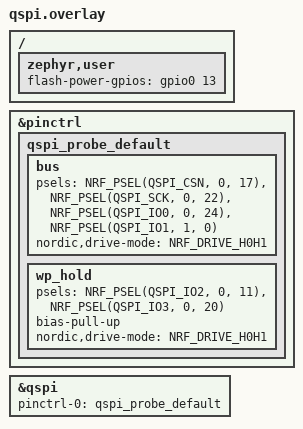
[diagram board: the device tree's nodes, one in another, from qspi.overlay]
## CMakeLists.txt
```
cmake_minimum_required(VERSION 3.20.0)
option(JAVELIN_PROBE "Run the native Javelin dictionary reader from external flash" OFF)
if(JAVELIN_PROBE)
  list(APPEND EXTRA_CONF_FILE "${CMAKE_CURRENT_SOURCE_DIR}/javelin.conf")
endif()
find_package(Zephyr REQUIRED HINTS $ENV{ZEPHYR_BASE})
project(zen_r4_qspi_probe)
target_sources(app PRIVATE src/main.c)

option(QUAD_PROBE "Build the separate quad-read diagnostic image" OFF)
option(SCRATCH_PROBE "Build the scratch-sector program and erase diagnostic image" OFF)
option(TRACE_PROBE "Repeat quad reads for waveform capture and timing comparison" OFF)
option(XIP_PROBE "Compare mapped quad reads with EasyDMA" OFF)
if(TRACE_PROBE AND NOT SCRATCH_PROBE)
  message(FATAL_ERROR "TRACE_PROBE requires SCRATCH_PROBE")
endif()
if(XIP_PROBE AND (NOT SCRATCH_PROBE OR TRACE_PROBE))
  message(FATAL_ERROR "XIP_PROBE requires SCRATCH_PROBE and a separate build from TRACE_PROBE")
endif()
if(JAVELIN_PROBE AND (NOT SCRATCH_PROBE OR XIP_PROBE OR TRACE_PROBE))
  message(FATAL_ERROR "JAVELIN_PROBE requires SCRATCH_PROBE and its own build directory")
endif()
if(QUAD_PROBE OR SCRATCH_PROBE)
  target_sources(app PRIVATE src/quad.c)
  target_compile_definitions(app PRIVATE QUAD_PROBE=1)
endif()
if(SCRATCH_PROBE)
  target_sources(app PRIVATE src/scratch.c)
  target_compile_definitions(app PRIVATE SCRATCH_PROBE=1)
endif()
if(TRACE_PROBE)
  target_sources(app PRIVATE src/trace.c)
  target_compile_definitions(app PRIVATE TRACE_PROBE=1)
endif()
if(XIP_PROBE OR JAVELIN_PROBE)
  target_sources(app PRIVATE src/mapped.c)
endif()
if(XIP_PROBE)
  target_compile_definitions(app PRIVATE XIP_PROBE=1)
endif()
if(JAVELIN_PROBE)
  include(javelin.cmake)
endif()
```

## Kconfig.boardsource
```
# The vendor board defconfig also configures the ZMK application. Declare
# those settings here so the same board can build this standalone probe.
source "Kconfig.zephyr"

config ZMK_KEYBOARD_NAME
	string

config ZMK_SPLIT_ROLE_CENTRAL
	bool

config ZMK_SPLIT
	bool

config ZMK_USB
	bool "Vendor ZMK USB default"

config ZMK_STUDIO
	bool "Vendor ZMK Studio default"

config ZMK_STUDIO_LOCKING
	bool "Vendor ZMK Studio locking default"

config ZMK_BLE
	bool "Vendor ZMK BLE default"

config ZMK_SLEEP
	bool "Vendor ZMK sleep default"

config ZMK_DISPLAY
	bool

config ZMK_DISPLAY_BLANK_ON_IDLE
	bool
```

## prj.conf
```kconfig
CONFIG_GPIO=y
CONFIG_PINCTRL=y
CONFIG_NRFX_QSPI=y

CONFIG_BUILD_OUTPUT_UF2=y
CONFIG_BUILD_OUTPUT_UF2_FAMILY_ID="0xada52840"
CONFIG_USE_DT_CODE_PARTITION=y

CONFIG_USB_DEVICE_STACK=y
CONFIG_USB_DEVICE_INITIALIZE_AT_BOOT=n
CONFIG_USB_DEVICE_PRODUCT="Zen R4 QSPI Probe"
CONFIG_SERIAL=y
CONFIG_CONSOLE=y
CONFIG_UART_CONSOLE=y
CONFIG_UART_LINE_CTRL=y

CONFIG_LOG=y
CONFIG_LOG_MODE_IMMEDIATE=y
CONFIG_LOG_PRINTK=n
CONFIG_USE_SEGGER_RTT=y
CONFIG_LOG_BACKEND_RTT=y
CONFIG_LOG_BACKEND_UART=n
```

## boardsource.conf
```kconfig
# The standalone probe uses nrfx QSPI and never uses Zephyr SPI or NVS settings.
CONFIG_SPI_NRFX=n
CONFIG_NVS=n
CONFIG_FLASH_MAP=n
CONFIG_FLASH_PAGE_LAYOUT=n
CONFIG_FLASH=n
CONFIG_ZMK_USB=n
CONFIG_ZMK_STUDIO=n
CONFIG_ZMK_BLE=n
CONFIG_ZMK_SLEEP=n
CONFIG_USB_DEVICE_PRODUCT="Boardsource QSPI Probe"
```

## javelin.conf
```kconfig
CONFIG_CPP=y
CONFIG_STD_CPP20=y
CONFIG_MAIN_STACK_SIZE=3072
```

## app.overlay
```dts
#include "qspi.overlay"

/ {
	chosen {
		zephyr,console = &probe_cdc;
	};
};

&zephyr_udc0 {
	probe_cdc: probe_cdc {
		compatible = "zephyr,cdc-acm-uart";
	};
};
```

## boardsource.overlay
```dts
#include "../../config/boardsource-wireless-corne/qspi.dtsi"

/ {
	chosen {
		zephyr,console = &probe_cdc;
	};
};

&zephyr_udc0 {
	probe_cdc: probe_cdc {
		compatible = "zephyr,cdc-acm-uart";
	};
};
```

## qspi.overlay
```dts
#include <zephyr/dt-bindings/gpio/gpio.h>
#include <zephyr/dt-bindings/pinctrl/nrf-pinctrl.h>

/ {
	zephyr,user {
		flash-power-gpios = <&gpio0 13 GPIO_ACTIVE_HIGH>;
	};
};

&pinctrl {
	qspi_probe_default: qspi_probe_default {
		bus {
			psels = <NRF_PSEL(QSPI_CSN, 0, 17)>,
				<NRF_PSEL(QSPI_SCK, 0, 22)>,
				<NRF_PSEL(QSPI_IO0, 0, 24)>,
				<NRF_PSEL(QSPI_IO1, 1, 0)>;
			nordic,drive-mode = <NRF_DRIVE_H0H1>;
		};
		wp_hold {
			psels = <NRF_PSEL(QSPI_IO2, 0, 11)>,
				<NRF_PSEL(QSPI_IO3, 0, 20)>;
			bias-pull-up;
			nordic,drive-mode = <NRF_DRIVE_H0H1>;
		};
	};
};

&qspi {
	status = "okay";
	pinctrl-0 = <&qspi_probe_default>;
	pinctrl-names = "default";
};
```

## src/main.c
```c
#include <nrfx_qspi.h>

#ifdef QUAD_PROBE
#include "quad.h"
#endif
#ifdef SCRATCH_PROBE
#include "scratch.h"
#endif

#include <zephyr/device.h>
#include <zephyr/devicetree.h>
#include <zephyr/drivers/gpio.h>
#include <zephyr/drivers/pinctrl.h>
#include <zephyr/drivers/uart.h>
#include <zephyr/kernel.h>
#include <zephyr/logging/log.h>
#include <zephyr/sys/printk.h>
#include <zephyr/usb/usb_device.h>

LOG_MODULE_REGISTER(qspi_probe);

#define QSPI_NODE DT_NODELABEL(qspi)

PINCTRL_DT_DEFINE(QSPI_NODE);

static const struct gpio_dt_spec flash_power =
	GPIO_DT_SPEC_GET(DT_PATH(zephyr_user), flash_power_gpios);
static const struct gpio_dt_spec status_led =
	GPIO_DT_SPEC_GET(DT_NODELABEL(blue_led), gpios);
static const struct device *const console = DEVICE_DT_GET(DT_CHOSEN(zephyr_console));

static const nrf_qspi_cinstr_conf_t read_id = {
	.opcode = 0x9f,
	.length = NRF_QSPI_CINSTR_LEN_4B,
	.io2_level = true,
	.io3_level = true,
	.wipwait = false,
	.wren = false,
};

struct probe_result {
	const char *failure;
	int gpio_or_pinctrl_error;
	nrfx_err_t nrfx_error;
	bool id_read;
	uint8_t id[3];
	uint8_t data[16] __aligned(4);
#ifdef QUAD_PROBE
	struct quad_result quad;
#endif
#ifdef SCRATCH_PROBE
	struct scratch_result scratch;
#endif
};

static void run_probe(struct probe_result *result)
{
	nrfx_qspi_config_t config = NRFX_QSPI_DEFAULT_CONFIG(
		NRF_QSPI_PIN_NOT_CONNECTED, NRF_QSPI_PIN_NOT_CONNECTED,
		NRF_QSPI_PIN_NOT_CONNECTED, NRF_QSPI_PIN_NOT_CONNECTED,
		NRF_QSPI_PIN_NOT_CONNECTED, NRF_QSPI_PIN_NOT_CONNECTED);

	/* Zephyr pinctrl supplies both the pin assignments and GPIO configuration. */
	config.skip_gpio_cfg = true;
	config.skip_psel_cfg = true;
	config.phy_if.sck_freq = NRF_QSPI_FREQ_DIV16;

	printk("Enabling switched flash VCC\n");
	if (!gpio_is_ready_dt(&flash_power)) {
		result->failure = "VCC GPIO device unavailable";
		return;
	}
	result->gpio_or_pinctrl_error = gpio_pin_configure_dt(&flash_power, GPIO_OUTPUT_ACTIVE);
	if (result->gpio_or_pinctrl_error) {
		result->failure = "VCC GPIO configuration";
		return;
	}
	k_msleep(50);

	printk("Applying QSPI pinctrl\n");
	result->gpio_or_pinctrl_error =
		pinctrl_apply_state(PINCTRL_DT_DEV_CONFIG_GET(QSPI_NODE), PINCTRL_STATE_DEFAULT);
	if (result->gpio_or_pinctrl_error) {
		result->failure = "QSPI pinctrl";
		return;
	}

	printk("Initializing Nordic QSPI (2 MHz, FASTREAD, 24-bit address)\n");
	result->nrfx_error = nrfx_qspi_init(&config, NULL, NULL);
	if (result->nrfx_error != NRFX_SUCCESS) {
		result->failure = "nrfx_qspi_init";
		return;
	}

	printk("Activating QSPI\n");
	result->nrfx_error = nrfx_qspi_activate(true);
	if (result->nrfx_error != NRFX_SUCCESS) {
		result->failure = "nrfx_qspi_activate";
		return;
	}

	printk("Reading JEDEC ID (0x9F)\n");
	result->nrfx_error = nrfx_qspi_cinstr_xfer(&read_id, NULL, result->id);
	if (result->nrfx_error != NRFX_SUCCESS) {
		result->failure = "JEDEC ID transfer";
		return;
	}
	result->id_read = true;

	if (result->id[0] != 0xef || result->id[1] != 0x40 || result->id[2] != 0x18) {
		result->failure = "unexpected JEDEC ID";
		return;
	}

	printk("Reading 16 bytes at 0x000000 with FASTREAD (0x0B)\n");
	result->nrfx_error = nrfx_qspi_read(result->data, sizeof(result->data), 0);
	if (result->nrfx_error != NRFX_SUCCESS) {
		result->failure = "FASTREAD transfer";
		return;
	}
#ifdef SCRATCH_PROBE
	run_scratch_probe(&config, &result->scratch, &result->quad);
#elif defined(QUAD_PROBE)
	run_quad_probe(&config, &result->quad, 0, 64 * 1024);
#endif
}

static void print_result(const struct probe_result *result)
{
	if (result->id_read) {
		printk("JEDEC ID: %02X %02X %02X (expected EF 40 18)\n",
		       result->id[0], result->id[1], result->id[2]);
	}
	if (result->failure) {
		printk("FAIL: %s; Zephyr rc=%d, nrfx rc=0x%08x\n",
		       result->failure, result->gpio_or_pinctrl_error, (unsigned int)result->nrfx_error);
		return;
	}

	printk("FASTREAD 0x000000:");
	for (size_t i = 0; i < sizeof(result->data); i++) {
		printk(" %02X", result->data[i]);
	}
#ifdef SCRATCH_PROBE
	printk("\nScratch %s (nrfx rc=0x%08x)\n",
	       result->scratch.outcome, (unsigned int)result->scratch.error);
	if (result->scratch.cleanup) {
		printk("Scratch cleanup %s (nrfx rc=0x%08x)\n",
		       result->scratch.cleanup, (unsigned int)result->scratch.cleanup_error);
	}
#endif
#ifdef QUAD_PROBE
	if (result->quad.outcome) {
		printk("\nQuad %s (compared %u bytes, lane mask 0x%x, nrfx rc=0x%08x)\n",
		       result->quad.outcome, result->quad.compared_bytes, result->quad.lane_coverage,
		       (unsigned int)result->quad.error);
#ifdef XIP_PROBE
		if (result->quad.mapped.outcome) {
			printk("XIP %s (matched %u words, nrfx rc=0x%08x)\n",
			       result->quad.mapped.outcome, result->quad.mapped.matched_words,
			       (unsigned int)result->quad.mapped.dma_error);
		}
#endif
#ifdef JAVELIN_PROBE
		if (result->quad.javelin_outcome) {
			printk("Javelin %s\n", result->quad.javelin_outcome);
			if (result->quad.phrase[0]) {
				printk("Javelin phrase: %s\n", result->quad.phrase);
			}
		}
#endif
		if (result->quad.restore_error != NRFX_SUCCESS) {
			printk("Quad SR2 restore failed: nrfx rc=0x%08x; power-cycle the flash\n",
			       (unsigned int)result->quad.restore_error);
		}
	}
#else
	printk("\nPASS: JEDEC ID and 16-byte single-data-line read completed\n");
#endif
}

int main(void)
{
	struct probe_result result = {.nrfx_error = NRFX_SUCCESS};
	uint32_t dtr = 0;
	bool led_ready = gpio_is_ready_dt(&status_led) &&
			 gpio_pin_configure_dt(&status_led, GPIO_OUTPUT_ACTIVE) == 0;
	int rc = device_is_ready(console) ? usb_enable(NULL) : -ENODEV;

	if (rc) {
		LOG_ERR("USB CDC startup failed: %d", rc);
		for (;;) {
			if (led_ready) {
				gpio_pin_toggle_dt(&status_led);
			}
			k_msleep(120);
		}
	}

	while (!dtr) {
		rc = uart_line_ctrl_get(console, UART_LINE_CTRL_DTR, &dtr);
		if (rc) {
			LOG_ERR("CDC DTR query failed: %d", rc);
		}
		k_msleep(100);
	}
	if (led_ready) {
		gpio_pin_set_dt(&status_led, 0);
	}

#ifdef TRACE_PROBE
	printk("\nZen R4 QSPI trace ready. Arm the analyzer, then send t.\n");
	for (;;) {
		unsigned char key;

		if (uart_poll_in(console, &key) == 0 && key == 't') {
			break;
		}
		k_msleep(20);
	}
#elif defined(XIP_PROBE)
	printk("\nZen R4 QSPI probe - mapped quad data reads\n");
#elif defined(JAVELIN_PROBE)
	printk("\nZen R4 QSPI probe - native Javelin mapped dictionary\n");
#elif defined(SCRATCH_PROBE)
	printk("\nZen R4 QSPI probe - scratch-sector program, read and erase\n");
#elif defined(QUAD_PROBE)
	printk("\n%s - quad output with volatile QE if needed\n", CONFIG_USB_DEVICE_PRODUCT);
#else
	printk("\n%s - read only\n", CONFIG_USB_DEVICE_PRODUCT);
#endif
	run_probe(&result);
	for (;;) {
		print_result(&result);
		k_sleep(K_SECONDS(3));
	}
}
```

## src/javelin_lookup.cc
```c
#include "javelin_lookup.h"

#include "console.h"
#include "dictionary/compact_map_dictionary.h"
#include "dictionary/dictionary_definition.h"
#include "flash.h"
#include "xip_load.h"

#include <nrf.h>
#include <nrf52_erratas.h>
#include <string.h>
#include <zephyr/kernel.h>
#include <zephyr/sys/printk.h>

// These hooks belong to dictionary editing and console commands. This image
// exercises read-only lookups, so editing must never reach the flash driver.
void Flash::Write(const void *, const void *, size_t, FlashWriteMode)
{
	k_panic();
}

void Console::PrintfInternal(const char *, ...)
{
}

ConsoleWriter::ClassData ConsoleWriter::classData{};

const char *javelin_lookup_phrase(uintptr_t address, char *phrase)
{
	printk("Using synchronized XIP loads (erratum 118: %u, erratum 216: %u)\n",
	       nrf52_errata_118(), nrf52_errata_216());
	const auto *collection = reinterpret_cast<const uint8_t *>(address);
	if (xip_load_word(collection) != STENO_MAP_DICTIONARY_COLLECTION_MAGIC ||
	    (xip_load_word(collection + offsetof(StenoDictionaryCollection, dictionaryCount)) &
	     0xffff) != 1) {
		return "FAIL: mapped JSC4 header";
	}
	const auto definition_address =
		xip_load_word(collection + offsetof(StenoDictionaryCollection, dictionaries));
	const auto fixture_end = address + (javelin_fixture_end - javelin_fixture_start);
	if (definition_address < address ||
	    definition_address > fixture_end - sizeof(StenoCompactMapDictionaryDefinition)) {
		return "FAIL: mapped definition address";
	}
	StenoCompactMapDictionaryDefinition definition;
	copy_xip_bytes(&definition, reinterpret_cast<const void *>(definition_address),
		       sizeof(definition));
	if (definition.type != StenoDictionaryType::COMPACT_MAP ||
	    definition.maximumOutlineLength != 1) {
		return "FAIL: mapped compact dictionary definition";
	}
	StenoCompactMapDictionaryStrokesDefinition stroke_table;
	copy_xip_bytes(&stroke_table, definition.strokes, sizeof(stroke_table));
	definition.strokes = &stroke_table;
	auto *dictionary = new (definition) StenoCompactMapDictionary(definition);
	if (!dictionary) {
		return "FAIL: dictionary allocation";
	}

	const struct {
		uint32_t stroke;
		const char *outline;
		const char *expected;
	} strokes[] = {
		{0x14, "TP", "if"}, {0x80000, "-T", "the"}, {0x80108, "KAT", "cat"},
		{0x2, "S", "is"}, {0x80000, "-T", "the"}, {0x80108, "KAT", "cat"},
	};
	const char *outcome = "PASS: native Javelin lookups used mapped external flash";
	size_t size = 0;
	phrase[0] = '\0';
	for (const auto &step : strokes) {
		const StenoStroke stroke(step.stroke);
		auto result = dictionary->Lookup(&stroke, 1);
		if (!result.IsValid()) {
			outcome = "FAIL: native lookup returned no entry";
			break;
		}
		const char *word = result.GetText();
		const auto word_address = reinterpret_cast<uintptr_t>(word);
		const auto expected_size = strlen(step.expected);
		char word_copy[4];
		if (word_address < address || word_address >= fixture_end ||
		    fixture_end - word_address <= expected_size || expected_size >= sizeof(word_copy)) {
			outcome = "FAIL: native lookup did not return a mapped text address";
			result.Destroy();
			break;
		}
		copy_xip_bytes(word_copy, word, expected_size + 1);
		if (memcmp(word_copy, step.expected, expected_size + 1) != 0) {
			outcome = "FAIL: mapped lookup text differed from expected";
			result.Destroy();
			break;
		}
		printk("Native stroke %s -> %s at 0x%08x\n", step.outline, word_copy,
		       static_cast<unsigned int>(word_address));
		if (size) {
			phrase[size++] = ' ';
		}
		memcpy(phrase + size, word_copy, expected_size + 1);
		size += expected_size;
		result.Destroy();
	}
	delete dictionary;
	return outcome;
}
```

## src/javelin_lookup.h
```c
#ifndef ZEN_R4_JAVELIN_LOOKUP_H
#define ZEN_R4_JAVELIN_LOOKUP_H

#include <stdint.h>

#ifdef __cplusplus
extern "C" {
#endif

extern const uint8_t javelin_fixture_start[];
extern const uint8_t javelin_fixture_end[];

const char *javelin_lookup_phrase(uintptr_t address, char *phrase);
#define JAVELIN_PHRASE_SIZE 32

#ifdef __cplusplus
}
#endif

#endif
```

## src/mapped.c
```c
#include "mapped.h"
#include "scratch.h"

#include <zephyr/devicetree.h>
#include <zephyr/kernel.h>
#include <zephyr/sys/printk.h>

#define XIP_BASE DT_REG_ADDR_BY_NAME(DT_NODELABEL(qspi), qspi_mm)
#define PAGE_WORDS (QUAD_SAMPLE_SIZE / sizeof(uint32_t))

static uint32_t dma_page[2][PAGE_WORDS];

bool reactivate_after_xip(void)
{
	/* nRF52840 anomaly 215. Use only task/event registers until READY. */
	nrf_qspi_event_clear(NRF_QSPI, NRF_QSPI_EVENT_READY);
	nrf_qspi_task_trigger(NRF_QSPI, NRF_QSPI_TASK_ACTIVATE);
	for (unsigned int i = 0; i < 1000; i++) {
		if (nrf_qspi_event_check(NRF_QSPI, NRF_QSPI_EVENT_READY)) {
			nrf_qspi_event_clear(NRF_QSPI, NRF_QSPI_EVENT_READY);
			return true;
		}
		k_busy_wait(10);
	}
	return false;
}

void run_mapped_probe(struct mapped_result *result, uint32_t first_address)
{
	const uint32_t addresses[] = {first_address, result->second_address};
	const uint8_t patterns[] = {SCRATCH_FIRST_PATTERN, SCRATCH_SECOND_PATTERN};
	uintptr_t mismatch_address = 0;
	uint32_t mismatch_expected = 0;
	uint32_t mismatch_actual = 0;

	for (size_t page = 0; page < ARRAY_SIZE(addresses); page++) {
		result->dma_error = nrfx_qspi_read(dma_page[page], sizeof(dma_page[page]),
						 addresses[page]);
		if (result->dma_error != NRFX_SUCCESS) {
			result->outcome = "FAIL: quad EasyDMA reference read";
			return;
		}
		const uint8_t *reference = (const uint8_t *)dma_page[page];

		for (size_t byte = 0; byte < sizeof(dma_page[page]); byte++) {
			if (reference[byte] != ((uint8_t)byte ^ patterns[page])) {
				printk("Quad EasyDMA pattern mismatch at 0x%06x\n",
				       addresses[page] + (unsigned int)byte);
				result->outcome = "FAIL: quad EasyDMA reference differs from programmed pattern";
				return;
			}
		}
	}

	printk("Reading mapped quad pages at 0x%08x and 0x%08x\n",
	       (unsigned int)(XIP_BASE + addresses[0]), (unsigned int)(XIP_BASE + addresses[1]));
	for (size_t page = 0; page < ARRAY_SIZE(addresses); page++) {
		const volatile uint32_t *mapped =
			(const volatile uint32_t *)(XIP_BASE + addresses[page]);

		for (size_t word = 0; word < PAGE_WORDS; word++) {
			uint32_t actual = mapped[word];
			uint32_t expected = dma_page[page][word];

			if (actual == expected) {
				result->matched_words++;
			} else if (mismatch_address == 0) {
				mismatch_address = (uintptr_t)&mapped[word];
				mismatch_expected = expected;
				mismatch_actual = actual;
			}
		}
	}

	if (!reactivate_after_xip()) {
		result->reactivation_failed = true;
		result->outcome = "FAIL: QSPI did not become ready after mapped reads";
		return;
	}
	if (mismatch_address) {
		printk("Mapped mismatch at 0x%08x: expected %08x, got %08x\n",
		       (unsigned int)mismatch_address, mismatch_expected, mismatch_actual);
		result->outcome = "FAIL: mapped reads differ from quad EasyDMA";
		return;
	}
	result->outcome = "PASS: both mapped pages match quad EasyDMA";
}
```

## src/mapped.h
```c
#ifndef ZEN_R4_MAPPED_H
#define ZEN_R4_MAPPED_H

#include <nrfx_qspi.h>

struct mapped_result {
	const char *outcome;
	uint32_t second_address;
	unsigned int matched_words;
	nrfx_err_t dma_error;
	bool reactivation_failed;
};

void run_mapped_probe(struct mapped_result *result, uint32_t first_address);

#endif
```

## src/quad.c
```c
#include "quad.h"
#ifdef TRACE_PROBE
#include "trace.h"
#endif
#ifdef JAVELIN_PROBE
#include "mapped.h"
#include <zephyr/devicetree.h>
#endif

#include <string.h>
#include <zephyr/kernel.h>
#include <zephyr/sys/printk.h>

#define QUAD_ENABLE BIT(1)
#define STATUS_BUSY_OR_WRITE_ENABLED (BIT(0) | BIT(1))
static uint8_t single_data[QUAD_SAMPLE_SIZE] __aligned(4);
static uint8_t quad_data[QUAD_SAMPLE_SIZE] __aligned(4);

bool reactivate_after_xip(void)
{
	/* nRF52840 anomaly 215. Use only task/event registers until READY. */
	nrf_qspi_event_clear(NRF_QSPI, NRF_QSPI_EVENT_READY);
	nrf_qspi_task_trigger(NRF_QSPI, NRF_QSPI_TASK_ACTIVATE);
	for (unsigned int i = 0; i < 1000; i++) {
		if (nrf_qspi_event_check(NRF_QSPI, NRF_QSPI_EVENT_READY)) {
			nrf_qspi_event_clear(NRF_QSPI, NRF_QSPI_EVENT_READY);
			return true;
		}
		k_busy_wait(10);
	}
	return false;
}

static nrfx_err_t status_command(uint8_t opcode, const uint8_t *tx, uint8_t *rx)
{
	const nrf_qspi_cinstr_conf_t command = {
		.opcode = opcode,
		.length = tx || rx ? NRF_QSPI_CINSTR_LEN_2B : NRF_QSPI_CINSTR_LEN_1B,
		.io2_level = true,
		.io3_level = true,
		.wipwait = false,
		.wren = false,
	};

	return nrfx_qspi_cinstr_xfer(&command, tx, rx);
}

static nrfx_err_t set_volatile_sr2(uint8_t value)
{
	uint8_t status;
	nrfx_err_t rc = status_command(0x05, NULL, &status);

	if (rc != NRFX_SUCCESS) {
		return rc;
	}
	/* A preexisting WEL could turn the SR2 write into a nonvolatile write. */
	if (status & STATUS_BUSY_OR_WRITE_ENABLED) {
		return NRFX_ERROR_BUSY;
	}

	rc = status_command(0x50, NULL, NULL);
	if (rc != NRFX_SUCCESS) {
		return rc;
	}
	rc = status_command(0x31, &value, NULL);
	if (rc != NRFX_SUCCESS) {
		return rc;
	}

	k_msleep(2);
	rc = status_command(0x35, NULL, &status);
	if (rc != NRFX_SUCCESS) {
		return rc;
	}
	return status == value ? NRFX_SUCCESS : NRFX_ERROR_INTERNAL;
}

nrfx_err_t w25q128_enable_volatile_quad(void)
{
	uint8_t status;
	nrfx_err_t rc = status_command(0x35, NULL, &status);

	if (rc != NRFX_SUCCESS || (status & QUAD_ENABLE)) {
		return rc;
	}
	return set_volatile_sr2(status | QUAD_ENABLE);
}

static nrfx_err_t read_sample(nrfx_qspi_config_t *config, nrf_qspi_readoc_t mode,
			      uint32_t address, uint8_t *data)
{
	config->prot_if.readoc = mode;
	nrfx_err_t rc = nrfx_qspi_reconfigure(config);

	if (rc != NRFX_SUCCESS) {
		return rc;
	}
	return nrfx_qspi_read(data, sizeof(single_data), address);
}

static void report_quad_mismatch(uint32_t address)
{
	unsigned int mismatches = 0;
	uint8_t different = 0;
	uint8_t any_high = 0;
	uint8_t all_high = 0xf;

	for (size_t i = 0; i < sizeof(single_data); i++) {
		uint8_t actual = quad_data[i];
		uint8_t difference = single_data[i] ^ actual;

		if (difference && ++mismatches <= 8) {
			printk("Quad at 0x%06x: expected %02X, got %02X\n",
			       address + (unsigned int)i, single_data[i], actual);
		}
		different |= difference | (difference >> 4);
		any_high |= actual | (actual >> 4);
		all_high &= actual & (actual >> 4);
	}

	printk("Quad mismatches %u/%u; lane masks IO3..IO0: differ=0x%x always-high=0x%x always-low=0x%x\n",
	       mismatches, (unsigned int)sizeof(single_data), different & 0xf,
	       all_high, (unsigned int)(~any_high & 0xf));
}

void run_quad_probe(nrfx_qspi_config_t *config, struct quad_result *result,
		    uint32_t start, uint32_t length)
{
	uint8_t original_sr2;
	uint8_t seen_one = 0;
	uint8_t seen_zero = 0;

	result->restore_error = NRFX_SUCCESS;
	result->error = status_command(0x35, NULL, &original_sr2);
	if (result->error != NRFX_SUCCESS) {
		result->outcome = "FAIL: reading Status Register 2";
		return;
	}
	printk("Quad probe initial Status Register 2: 0x%02x\n", original_sr2);

	bool change_qe = (original_sr2 & QUAD_ENABLE) == 0;

	if (change_qe) {
		result->error = set_volatile_sr2(original_sr2 | QUAD_ENABLE);
		if (result->error != NRFX_SUCCESS) {
			result->outcome = "FAIL: setting or verifying volatile QE";
			result->restore_error = set_volatile_sr2(original_sr2);
			return;
		}
	}

	result->outcome = "INCONCLUSIVE: sampled data did not exercise both states on all lanes";
	for (uint32_t address = start; address < start + length; address += sizeof(single_data)) {
		result->error = read_sample(config, NRF_QSPI_READOC_FASTREAD, address, single_data);
		if (result->error != NRFX_SUCCESS) {
			result->outcome = "FAIL: single-data-line reference read";
			break;
		}
		result->error = read_sample(config, NRF_QSPI_READOC_READ4O, address, quad_data);
		if (result->error != NRFX_SUCCESS) {
			result->outcome = "FAIL: quad-output transfer";
			break;
		}
#ifdef TRACE_PROBE
		run_quad_trace(address, single_data);
#endif
		if (memcmp(single_data, quad_data, sizeof(single_data)) != 0) {
			report_quad_mismatch(address);
			nrfx_err_t dual_rc =
				read_sample(config, NRF_QSPI_READOC_READ2O, address, quad_data);
			if (dual_rc != NRFX_SUCCESS) {
				printk("Dual-output control transfer failed: nrfx rc=0x%08x\n",
				       (unsigned int)dual_rc);
			} else {
				printk("Dual-output control %s\n",
				       memcmp(single_data, quad_data, sizeof(single_data)) == 0
					       ? "matched" : "differed");
			}
			result->outcome = "FAIL: single and quad samples differ";
			break;
		}
		result->compared_bytes += sizeof(single_data);
		for (size_t i = 0; i < sizeof(single_data); i++) {
			uint8_t byte = single_data[i];

			seen_one |= byte | (byte >> 4);
			seen_zero |= (uint8_t)~byte | ((uint8_t)~byte >> 4);
		}
		result->lane_coverage = (seen_one & seen_zero) & 0xf;
		if (result->lane_coverage == 0xf) {
			result->outcome = "PASS: quad output matched reference with both states on IO0-IO3";
#ifdef XIP_PROBE
			run_mapped_probe(&result->mapped, address);
			if (result->mapped.reactivation_failed) {
				return;
			}
#endif
#ifdef JAVELIN_PROBE
			const uintptr_t mapped_address =
				DT_REG_ADDR_BY_NAME(DT_NODELABEL(qspi), qspi_mm) + address;
			printk("Opening external JSC4 at 0x%08x\n", (unsigned int)mapped_address);
			result->javelin_outcome = javelin_lookup_phrase(mapped_address, result->phrase);
			if (!reactivate_after_xip()) {
				result->javelin_reactivation_failed = true;
				return;
			}
#endif
			break;
		}
	}

	if (change_qe) {
		result->restore_error = set_volatile_sr2(original_sr2);
	}
}
```

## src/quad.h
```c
#ifndef ZEN_R4_QUAD_H
#define ZEN_R4_QUAD_H

#include <nrfx_qspi.h>
#ifdef XIP_PROBE
#include "mapped.h"
#endif
#ifdef JAVELIN_PROBE
#include "javelin_lookup.h"
#endif

struct quad_result {
	const char *outcome;
	nrfx_err_t error;
	nrfx_err_t restore_error;
	uint32_t compared_bytes;
	uint8_t lane_coverage;
#ifdef XIP_PROBE
	struct mapped_result mapped;
#endif
#ifdef JAVELIN_PROBE
	const char *javelin_outcome;
	char phrase[JAVELIN_PHRASE_SIZE];
	bool javelin_reactivation_failed;
#endif
};

#define QUAD_SAMPLE_SIZE 256

nrfx_err_t w25q128_enable_volatile_quad(void);
bool reactivate_after_xip(void);

void run_quad_probe(nrfx_qspi_config_t *config, struct quad_result *result,
		    uint32_t start, uint32_t length);

#endif
```

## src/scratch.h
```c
#ifndef ZEN_R4_SCRATCH_H
#define ZEN_R4_SCRATCH_H

#include "quad.h"

#define SCRATCH_FIRST_PATTERN 0xa5
#define SCRATCH_SECOND_PATTERN 0x3c

struct scratch_result {
	const char *outcome;
	const char *cleanup;
	nrfx_err_t error;
	nrfx_err_t cleanup_error;
};

void run_scratch_probe(nrfx_qspi_config_t *config, struct scratch_result *result,
		       struct quad_result *quad);

#endif
```

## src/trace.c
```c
#include "trace.h"
#include "quad.h"

#include <hal/nrf_gpio.h>
#include <string.h>
#include <zephyr/kernel.h>
#include <zephyr/sys/printk.h>

#define TRACE_READS 8

static uint8_t trace_data[QUAD_SAMPLE_SIZE] __aligned(4);

static nrfx_err_t set_timing(nrf_gpio_pin_drive_t drive, uint8_t rx_delay)
{
	nrfx_err_t rc = nrfx_qspi_deactivate();
	nrf_qspi_pins_t pins;

	if (rc != NRFX_SUCCESS) {
		return rc;
	}
	nrf_qspi_pins_get(NRF_QSPI, &pins);
	const uint8_t bus_pins[] = {
		pins.sck_pin, pins.csn_pin, pins.io0_pin, pins.io1_pin, pins.io2_pin, pins.io3_pin,
	};

	for (size_t i = 0; i < ARRAY_SIZE(bus_pins); i++) {
		nrf_gpio_reconfigure(bus_pins[i], NULL, NULL, NULL, &drive, NULL);
	}
	nrf_qspi_iftiming_set(NRF_QSPI, rx_delay);
	return NRFX_SUCCESS;
}

void run_quad_trace(uint32_t address, const uint8_t *expected)
{
	const uint8_t initial_delay =
		(NRF_QSPI->IFTIMING & QSPI_IFTIMING_RXDELAY_Msk) >> QSPI_IFTIMING_RXDELAY_Pos;
	const struct {
		const char *label;
		nrf_gpio_pin_drive_t drive;
		uint8_t rx_delay;
	} settings[] = {
		{"standard drive", NRF_GPIO_PIN_S0S1, initial_delay},
		{"high drive", NRF_GPIO_PIN_H0H1, initial_delay},
		{"high drive, delayed sampling", NRF_GPIO_PIN_H0H1, 4},
	};

	for (size_t setting = 0; setting < ARRAY_SIZE(settings); setting++) {
		nrfx_err_t rc = set_timing(settings[setting].drive, settings[setting].rx_delay);
		unsigned int matched = 0;
		unsigned int mismatched_bytes = 0;

		printk("Trace %u: %s, RXDELAY=%u, %u reads from 0x%06x\n",
		       (unsigned int)setting + 1, settings[setting].label,
		       settings[setting].rx_delay, TRACE_READS, address);
		k_msleep(400);
		for (unsigned int trial = 0; trial < TRACE_READS && rc == NRFX_SUCCESS; trial++) {
			rc = nrfx_qspi_read(trace_data, sizeof(trace_data), address);
			if (rc != NRFX_SUCCESS) {
				break;
			}
			unsigned int mismatches = 0;

			for (size_t i = 0; i < sizeof(trace_data); i++) {
				mismatches += trace_data[i] != expected[i];
			}
			mismatched_bytes += mismatches;
			matched += mismatches == 0;
			k_msleep(20);
		}
		printk("Trace %u result: %u/%u exact reads, %u mismatched bytes, nrfx rc=0x%08x\n",
		       (unsigned int)setting + 1, matched, TRACE_READS, mismatched_bytes,
		       (unsigned int)rc);
	}

	nrfx_err_t rc = set_timing(NRF_GPIO_PIN_H0H1, initial_delay);

	if (rc != NRFX_SUCCESS) {
		printk("Trace timing restore failed: nrfx rc=0x%08x\n", (unsigned int)rc);
	}
}
```

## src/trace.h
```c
#ifndef ZEN_R4_TRACE_H
#define ZEN_R4_TRACE_H

#include <stdint.h>

void run_quad_trace(uint32_t address, const uint8_t *expected);

#endif
```

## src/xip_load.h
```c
#ifndef ZEN_R4_XIP_LOAD_H
#define ZEN_R4_XIP_LOAD_H

#include <stddef.h>
#include <stdint.h>

// Keep subword reads out of the memory window (erratum 118), and serialize
// each load before using its value in a dependent access (erratum 216).
static inline uint32_t xip_load_word(const void *address)
{
	const auto value = *static_cast<const volatile uint32_t *>(address);
	asm volatile("dsb" ::: "memory");
	return value;
}

static inline uint8_t xip_load_byte(const void *address)
{
	const auto offset = reinterpret_cast<uintptr_t>(address);
	const auto word = xip_load_word(reinterpret_cast<const void *>(offset & ~uintptr_t(3)));
	return static_cast<uint8_t>(word >> (8 * (offset & 3)));
}

static inline uint32_t xip_load_u24(const void *address)
{
	const auto *bytes = static_cast<const uint8_t *>(address);
	const uint32_t low = xip_load_byte(bytes);
	const uint32_t middle = xip_load_byte(bytes + 1);
	const uint32_t high = xip_load_byte(bytes + 2);
	return low | (middle << 8) | (high << 16);
}

static inline void copy_xip_bytes(void *destination, const void *address, size_t length)
{
	auto *out = static_cast<uint8_t *>(destination);
	const auto *in = static_cast<const uint8_t *>(address);
	for (size_t i = 0; i < length; ++i) {
		out[i] = xip_load_byte(in + i);
	}
}

#endif
```
